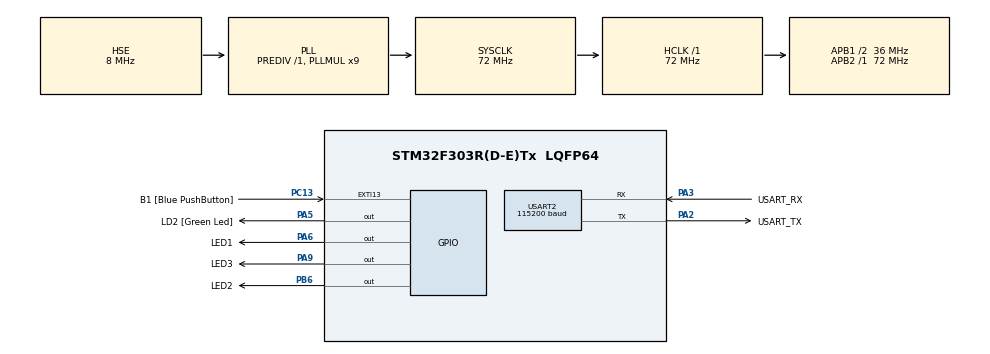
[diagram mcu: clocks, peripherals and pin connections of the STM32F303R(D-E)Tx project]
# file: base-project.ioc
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Dma.Request0=USART2_RX
Dma.Request1=USART2_TX
Dma.USART2_RX.0.Direction=DMA_PERIPH_TO_MEMORY
Dma.USART2_RX.0.Instance=DMA1_Channel6
Dma.USART2_RX.0.MemDataAlignment=DMA_MDATAALIGN_BYTE
Dma.USART2_RX.0.MemInc=DMA_MINC_ENABLE
Dma.USART2_RX.0.Mode=DMA_NORMAL
Dma.USART2_RX.0.PeriphDataAlignment=DMA_PDATAALIGN_BYTE
Dma.USART2_RX.0.PeriphInc=DMA_PINC_DISABLE
Dma.USART2_RX.0.Priority=DMA_PRIORITY_LOW
Dma.USART2_TX.1.Direction=DMA_MEMORY_TO_PERIPH
Dma.USART2_TX.1.Instance=DMA1_Channel7
Dma.USART2_TX.1.MemDataAlignment=DMA_MDATAALIGN_BYTE
Dma.USART2_TX.1.MemInc=DMA_MINC_ENABLE
Dma.USART2_TX.1.Mode=DMA_NORMAL
Dma.USART2_TX.1.PeriphDataAlignment=DMA_PDATAALIGN_BYTE
Dma.USART2_TX.1.PeriphInc=DMA_PINC_DISABLE
Dma.USART2_TX.1.Priority=DMA_PRIORITY_LOW
FREERTOS.BinarySemaphores01=myBinarySem01,Static,myBinarySem01ControlBlock;myBinarySem02,Static,myBinarySem02ControlBlock;myBinarySem03,Static,myBinarySem03ControlBlock
FREERTOS.Tasks01=defaultTask,24,128,StartDefaultTask,Default,NULL,Dynamic,NULL,NULL;myTask02,8,128,StartTask02,Default,NULL,Static,myTask02Buffer,myTask02ControlBlock;myTask03,8,128,StartTask03,Default,NULL,Static,myTask03Buffer,myTask03ControlBlock;myTask04,8,128,StartTask04,Default,NULL,Static,myTask04Buffer,myTask04ControlBlock
FREERTOS.Timers01=myTimer01,Callback01,osTimerPeriodic,Default,NULL,Static,myTimer01ControlBlock
Mcu.Family=STM32F3
Mcu.Name=STM32F303R(D-E)Tx
Mcu.Package=LQFP64
NVIC.DMA1_Channel6_IRQn=true\:5\:0\:false\:false\:true\:true\:false\:true
NVIC.DMA1_Channel7_IRQn=true\:5\:0\:false\:false\:true\:true\:false\:true
NVIC.PriorityGroup=NVIC_PRIORITYGROUP_4
NVIC.TIM1_UP_TIM16_IRQn=true\:0\:0\:false\:false\:true\:false\:false\:true
NVIC.TimeBase=TIM1_UP_TIM16_IRQn
NVIC.TimeBaseIP=TIM1
NVIC.USART2_IRQn=true\:5\:0\:false\:false\:true\:true\:true\:true
PA13.GPIO_Label=TMS
PA13.Mode=Serial_Wire
PA13.Signal=SYS_JTMS-SWDIO
PA14.GPIO_Label=TCK
PA14.Mode=Serial_Wire
PA14.Signal=SYS_JTCK-SWCLK
PA2.GPIO_Label=USART_TX
PA2.GPIO_Mode=GPIO_MODE_AF_PP
PA2.GPIO_PuPd=GPIO_NOPULL
PA2.GPIO_Speed=GPIO_SPEED_FREQ_LOW
PA2.Mode=Asynchronous
PA2.Signal=USART2_TX
PA3.GPIO_Label=USART_RX
PA3.GPIO_Mode=GPIO_MODE_AF_PP
PA3.GPIO_PuPd=GPIO_NOPULL
PA3.GPIO_Speed=GPIO_SPEED_FREQ_LOW
PA3.Mode=Asynchronous
PA3.Signal=USART2_RX
PA5.GPIO_Label=LD2 [Green Led]
PA5.GPIO_Mode=GPIO_MODE_OUTPUT_PP
PA5.GPIO_PuPd=GPIO_NOPULL
PA5.GPIO_Speed=GPIO_SPEED_FREQ_LOW
PA5.Signal=GPIO_Output
PA6.GPIO_Label=LED1
PA6.Signal=GPIO_Output
PA9.GPIO_Label=LED3
PA9.Signal=GPIO_Output
PB3.GPIO_Label=SWO
PB3.Signal=SYS_JTDO-TRACESWO
PB6.GPIO_Label=LED2
PB6.Signal=GPIO_Output
PC13.GPIO_Label=B1 [Blue PushButton]
PC13.GPIO_ModeDefaultEXTI=GPIO_MODE_IT_FALLING
PC13.Signal=GPXTI13
PC14-OSC32_IN.Mode=LSE-External-Oscillator
PC14-OSC32_IN.Signal=RCC_OSC32_IN
PC15-OSC32_OUT.Mode=LSE-External-Oscillator
PC15-OSC32_OUT.Signal=RCC_OSC32_OUT
PF0-OSC_IN.Mode=HSE-External-Clock-Source
PF0-OSC_IN.Signal=RCC_OSC_IN
PF1-OSC_OUT.Signal=RCC_OSC_OUT
ProjectManager.HeapSize=0x200
ProjectManager.StackSize=0x400
ProjectManager.TargetToolchain=STM32CubeIDE
RCC.AHBFreq_Value=72000000
RCC.APB1CLKDivider=RCC_HCLK_DIV2
RCC.APB1Freq_Value=36000000
RCC.APB1TimFreq_Value=72000000
RCC.APB2Freq_Value=72000000
RCC.APB2TimFreq_Value=72000000
RCC.CortexFreq_Value=72000000
RCC.HCLKFreq_Value=72000000
RCC.HSE_VALUE=8000000
RCC.HSI_VALUE=8000000
RCC.PLLM=8
RCC.PLLMUL=RCC_PLL_MUL9
RCC.PLLN=336
RCC.PLLP=RCC_PLLP_DIV4
RCC.PLLQ=7
RCC.PLLSourceVirtual=RCC_PLLSOURCE_HSE
RCC.RCC_PLLsource_Clock_Source_FROM_HSE=RCC_HSE_PREDIV_DIV2
RCC.SYSCLKFreq_VALUE=72000000
RCC.SYSCLKSourceVirtual=RCC_SYSCLKSOURCE_PLLCLK
RCC.USBFreq_Value=72000000
USART2.BaudRate=115200
USART2.VirtualMode-Asynchronous=VM_ASYNC
VP_FREERTOS_VS_CMSIS_V2.Mode=CMSIS_V2
VP_SYS_VS_tim1.Mode=TIM1
board=NUCLEO-F303RE

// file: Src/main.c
/* USER CODE BEGIN Header */
/**
  ******************************************************************************
  * @file           : main.c
  * @brief          : Main program body
  ******************************************************************************
  * @attention
  *
  * <h2><center>&copy; Copyright (c) 2019 STMicroelectronics.
  * All rights reserved.</center></h2>
  *
  * This software component is licensed by ST under Ultimate Liberty license
  * SLA0044, the "License"; You may not use this file except in compliance with
  * the License. You may obtain a copy of the License at:
  *                             www.st.com/SLA0044
  *
  ******************************************************************************
  */
/* USER CODE END Header */

#include "main.h"
#include "cmsis_os.h"

/* USER CODE BEGIN Includes */
#include "leds.h"
/* USER CODE END Includes */

UART_HandleTypeDef huart2;

typedef StaticTask_t osStaticThreadDef_t;
typedef StaticTimer_t osStaticTimerDef_t;
typedef StaticSemaphore_t osStaticSemaphoreDef_t;
osThreadId_t defaultTaskHandle;
osThreadId_t myTask02Handle;
uint32_t myTask02Buffer[ 128 ];
osStaticThreadDef_t myTask02ControlBlock;
osThreadId_t myTask03Handle;
uint32_t myTask03Buffer[ 128 ];
osStaticThreadDef_t myTask03ControlBlock;
osThreadId_t myTask04Handle;
uint32_t myTask04Buffer[ 128 ];
osStaticThreadDef_t myTask04ControlBlock;
osTimerId_t myTimer01Handle;
osStaticTimerDef_t myTimer01ControlBlock;
osSemaphoreId_t myBinarySem01Handle;
osStaticSemaphoreDef_t myBinarySem01ControlBlock;
osSemaphoreId_t myBinarySem02Handle;
osStaticSemaphoreDef_t myBinarySem02ControlBlock;
osSemaphoreId_t myBinarySem03Handle;
osStaticSemaphoreDef_t myBinarySem03ControlBlock;

void SystemClock_Config(void);
static void MX_GPIO_Init(void);
static void MX_USART2_UART_Init(void);
void StartDefaultTask(void *argument);
void StartTask02(void *argument);
void StartTask03(void *argument);
void StartTask04(void *argument);
void Callback01(void *argument);

int main(void)
{

  /* MCU Configuration--------------------------------------------------------*/

  /* Reset of all peripherals, Initializes the Flash interface and the Systick. */
  HAL_Init();

  /* Configure the system clock */
  SystemClock_Config();

  /* Initialize all configured peripherals */
  MX_GPIO_Init();
  MX_USART2_UART_Init();

  osKernelInitialize();

  /* Create the semaphores(s) */
  /* definition and creation of myBinarySem01 */
  const osSemaphoreAttr_t myBinarySem01_attributes = {
    .name = "myBinarySem01",
    .cb_mem = &myBinarySem01ControlBlock,
    .cb_size = sizeof(myBinarySem01ControlBlock),
  };
  myBinarySem01Handle = osSemaphoreNew(1, 1, &myBinarySem01_attributes);

  /* definition and creation of myBinarySem02 */
  const osSemaphoreAttr_t myBinarySem02_attributes = {
    .name = "myBinarySem02",
    .cb_mem = &myBinarySem02ControlBlock,
    .cb_size = sizeof(myBinarySem02ControlBlock),
  };
  myBinarySem02Handle = osSemaphoreNew(1, 1, &myBinarySem02_attributes);

  /* definition and creation of myBinarySem03 */
  const osSemaphoreAttr_t myBinarySem03_attributes = {
    .name = "myBinarySem03",
    .cb_mem = &myBinarySem03ControlBlock,
    .cb_size = sizeof(myBinarySem03ControlBlock),
  };
  myBinarySem03Handle = osSemaphoreNew(1, 1, &myBinarySem03_attributes);

  /* Create the timer(s) */
  /* definition and creation of myTimer01 */
  const osTimerAttr_t myTimer01_attributes = {
    .name = "myTimer01",
    .cb_mem = &myTimer01ControlBlock,
    .cb_size = sizeof(myTimer01ControlBlock),
  };
  myTimer01Handle = osTimerNew(Callback01, osTimerPeriodic, NULL, &myTimer01_attributes);

  /* Create the thread(s) */
  /* definition and creation of defaultTask */
  const osThreadAttr_t defaultTask_attributes = {
    .name = "defaultTask",
    .priority = (osPriority_t) osPriorityNormal,
    .stack_size = 128
  };
  defaultTaskHandle = osThreadNew(StartDefaultTask, NULL, &defaultTask_attributes);

  /* definition and creation of myTask02 */
  const osThreadAttr_t myTask02_attributes = {
    .name = "myTask02",
    .stack_mem = &myTask02Buffer[0],
    .stack_size = sizeof(myTask02Buffer),
    .cb_mem = &myTask02ControlBlock,
    .cb_size = sizeof(myTask02ControlBlock),
    .priority = (osPriority_t) osPriorityLow,
  };
  myTask02Handle = osThreadNew(StartTask02, NULL, &myTask02_attributes);

  /* definition and creation of myTask03 */
  const osThreadAttr_t myTask03_attributes = {
    .name = "myTask03",
    .stack_mem = &myTask03Buffer[0],
    .stack_size = sizeof(myTask03Buffer),
    .cb_mem = &myTask03ControlBlock,
    .cb_size = sizeof(myTask03ControlBlock),
    .priority = (osPriority_t) osPriorityLow,
  };
  myTask03Handle = osThreadNew(StartTask03, NULL, &myTask03_attributes);

  /* definition and creation of myTask04 */
  const osThreadAttr_t myTask04_attributes = {
    .name = "myTask04",
    .stack_mem = &myTask04Buffer[0],
    .stack_size = sizeof(myTask04Buffer),
    .cb_mem = &myTask04ControlBlock,
    .cb_size = sizeof(myTask04ControlBlock),
    .priority = (osPriority_t) osPriorityLow,
  };
  myTask04Handle = osThreadNew(StartTask04, NULL, &myTask04_attributes);

  /* Start scheduler */
  osKernelStart();

  /* We should never get here as control is now taken by the scheduler */

  /* Infinite loop */
  while (1)
  {

  }
}

void SystemClock_Config(void)
{
  RCC_OscInitTypeDef RCC_OscInitStruct = {0};
  RCC_ClkInitTypeDef RCC_ClkInitStruct = {0};
  RCC_PeriphCLKInitTypeDef PeriphClkInit = {0};

  /** Initializes the CPU, AHB and APB busses clocks
  */
  RCC_OscInitStruct.OscillatorType = RCC_OSCILLATORTYPE_HSE;
  RCC_OscInitStruct.HSEState = RCC_HSE_BYPASS;
  RCC_OscInitStruct.HSIState = RCC_HSI_ON;
  RCC_OscInitStruct.PLL.PLLState = RCC_PLL_ON;
  RCC_OscInitStruct.PLL.PLLSource = RCC_PLLSOURCE_HSE;
  RCC_OscInitStruct.PLL.PLLMUL = RCC_PLL_MUL9;
  RCC_OscInitStruct.PLL.PREDIV = RCC_PREDIV_DIV1;
  if (HAL_RCC_OscConfig(&RCC_OscInitStruct) != HAL_OK)
  {
    Error_Handler();
  }
  /** Initializes the CPU, AHB and APB busses clocks
  */
  RCC_ClkInitStruct.ClockType = RCC_CLOCKTYPE_HCLK|RCC_CLOCKTYPE_SYSCLK
                              |RCC_CLOCKTYPE_PCLK1|RCC_CLOCKTYPE_PCLK2;
  RCC_ClkInitStruct.SYSCLKSource = RCC_SYSCLKSOURCE_PLLCLK;
  RCC_ClkInitStruct.AHBCLKDivider = RCC_SYSCLK_DIV1;
  RCC_ClkInitStruct.APB1CLKDivider = RCC_HCLK_DIV2;
  RCC_ClkInitStruct.APB2CLKDivider = RCC_HCLK_DIV1;

  if (HAL_RCC_ClockConfig(&RCC_ClkInitStruct, FLASH_LATENCY_2) != HAL_OK)
  {
    Error_Handler();
  }
  PeriphClkInit.PeriphClockSelection = RCC_PERIPHCLK_USART2;
  PeriphClkInit.Usart2ClockSelection = RCC_USART2CLKSOURCE_PCLK1;
  if (HAL_RCCEx_PeriphCLKConfig(&PeriphClkInit) != HAL_OK)
  {
    Error_Handler();
  }
}

static void MX_USART2_UART_Init(void)
{

  huart2.Instance = USART2;
  huart2.Init.BaudRate = 38400;
  huart2.Init.WordLength = UART_WORDLENGTH_8B;
  huart2.Init.StopBits = UART_STOPBITS_1;
  huart2.Init.Parity = UART_PARITY_NONE;
  huart2.Init.Mode = UART_MODE_TX_RX;
  huart2.Init.HwFlowCtl = UART_HWCONTROL_NONE;
  huart2.Init.OverSampling = UART_OVERSAMPLING_16;
  huart2.Init.OneBitSampling = UART_ONE_BIT_SAMPLE_DISABLE;
  huart2.AdvancedInit.AdvFeatureInit = UART_ADVFEATURE_NO_INIT;
  if (HAL_UART_Init(&huart2) != HAL_OK)
  {
    Error_Handler();
  }

}

static void MX_GPIO_Init(void)
{
  GPIO_InitTypeDef GPIO_InitStruct = {0};

  /* GPIO Ports Clock Enable */
  __HAL_RCC_GPIOC_CLK_ENABLE();
  __HAL_RCC_GPIOF_CLK_ENABLE();
  __HAL_RCC_GPIOA_CLK_ENABLE();
  __HAL_RCC_GPIOB_CLK_ENABLE();

  /*Configure GPIO pin Output Level */
  HAL_GPIO_WritePin(GPIOA, LD2_Pin|LED1_Pin|LED3_Pin, GPIO_PIN_RESET);

  /*Configure GPIO pin Output Level */
  HAL_GPIO_WritePin(LED2_GPIO_Port, LED2_Pin, GPIO_PIN_RESET);

  /*Configure GPIO pin : B1_Pin */
  GPIO_InitStruct.Pin = B1_Pin;
  GPIO_InitStruct.Mode = GPIO_MODE_IT_FALLING;
  GPIO_InitStruct.Pull = GPIO_NOPULL;
  HAL_GPIO_Init(B1_GPIO_Port, &GPIO_InitStruct);

  /*Configure GPIO pins : LD2_Pin LED1_Pin LED3_Pin */
  GPIO_InitStruct.Pin = LD2_Pin|LED1_Pin|LED3_Pin;
  GPIO_InitStruct.Mode = GPIO_MODE_OUTPUT_PP;
  GPIO_InitStruct.Pull = GPIO_NOPULL;
  GPIO_InitStruct.Speed = GPIO_SPEED_FREQ_LOW;
  HAL_GPIO_Init(GPIOA, &GPIO_InitStruct);

  /*Configure GPIO pin : LED2_Pin */
  GPIO_InitStruct.Pin = LED2_Pin;
  GPIO_InitStruct.Mode = GPIO_MODE_OUTPUT_PP;
  GPIO_InitStruct.Pull = GPIO_NOPULL;
  GPIO_InitStruct.Speed = GPIO_SPEED_FREQ_LOW;
  HAL_GPIO_Init(LED2_GPIO_Port, &GPIO_InitStruct);

}

void StartDefaultTask(void *argument)
{
  for(;;)
  {
    osDelay(1);
  }
}

void StartTask02(void *argument)
{
  for(;;)
  {
    osDelay(1);
  }
}

void StartTask03(void *argument)
{
  for(;;)
  {
    osDelay(1);
  }
}

void StartTask04(void *argument)
{
  for(;;)
  {
    osDelay(1);
  }
}

/* Callback01 function */
void Callback01(void *argument)
{
}

void HAL_TIM_PeriodElapsedCallback(TIM_HandleTypeDef *htim)
{
  if (htim->Instance == TIM1) {
    HAL_IncTick();
  }
}

void Error_Handler(void)
{
}

/************************ (C) COPYRIGHT STMicroelectronics *****END OF FILE****/
